# LPC15xx register map
File version: 0.7
CPU: CM3 r2p1, little endian, no MPU, no FPU, 3 interrupt priority bits
Registers are 32-bit, read-write, reset 0x0 unless marked. A register's access mark holds for its fields unless they carry their own. Offsets are from the block's base; [hi:lo] are bit positions.

## CRC — Cyclic Redundancy Check (CRC) engine
Base 0x1C010000
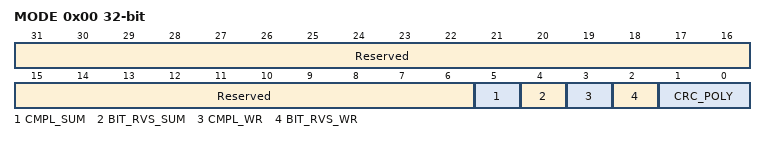
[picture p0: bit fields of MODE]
0x00 MODE — CRC mode register
  [31:6] Reserved — Always 0 when read
  [5] CMPL_SUM — CRC sum complement: 1= 1's complement for CRC_SUM 0=No 1's complement for CRC_SUM
  [4] BIT_RVS_SUM — CRC sum bit order: 1= Bit order reverse for CRC_SUM 0= No bit order reverse for CRC_SUM
  [3] CMPL_WR — Data complement: 1= 1's complement for CRC_WR_DATA 0= No 1's complement for CRC_WR_DATA
  [2] BIT_RVS_WR — Data bit order: 1= Bit order reverse for CRC_WR_DATA (per byte) 0= No bit order reverse for CRC_WR_DATA (per byte)
  [1:0] CRC_POLY — CRC polynom: 1X= CRC-32 polynomial 01= CRC-16 polynomial 00= CRC-CCITT polynomial
0x04 SEED reset 0xFFFF — CRC seed register
  [31:0] CRC_SEED — A write access to this register will load CRC seed value to CRC_SUM register with selected bit order and 1's complement pre-processes. A write access to this register will overrule the CRC calculation in progresses.
0x08 SUM ro reset 0xFFFF — CRC checksum register
  [31:0] CRC_SUM — The most recent CRC sum can be read through this register with selected bit order and 1's complement post-processes.
0x08 WR_DATA wo reset not defined (alternate view of SUM) — CRC data register
  [31:0] CRC_WR_DATA — Data written to this register will be taken to perform CRC calculation with selected bit order and 1's complement pre-process. Any write size 8, 16 or 32-bit are allowed and accept back-to-back transactions.

## WWDT — Windowed Watchdog Timer (WWDT)
Base 0x4002C000
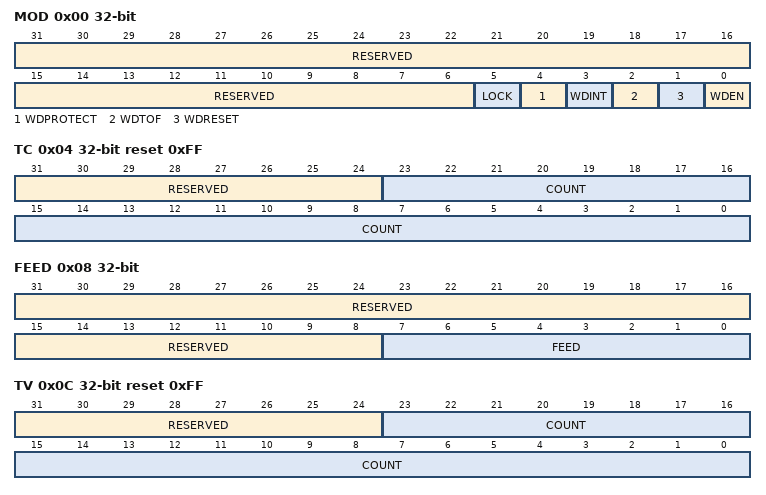
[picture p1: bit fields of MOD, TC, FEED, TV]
0x00 MOD — Watchdog mode register. This register contains the basic mode and status of the Watchdog Timer.
  [31:6] RESERVED — Reserved, user software should not write ones to reserved bits. The value read from a reserved bit is not defined.
  [5] LOCK — A 1 in this bit prevents disabling or powering down the watchdog oscillator. This bit can be set once by software and is only cleared by any reset.
  [4] WDPROTECT — Watchdog update mode. This bit can be set once by software and is only cleared by a reset.
    0=FLEXIBLE (Flexible. The watchdog time-out value (TC) can be changed at any time.); 1=THRESHOLD (Threshold. The watchdog time-out value (TC) can be changed only after the counter is below the value of WDWARNINT and WDWINDOW.)
  [3] WDINT — Warning interrupt flag. Set when the timer reaches the value in WDWARNINT. Cleared by software.
  [2] WDTOF — Watchdog time-out flag. Set when the watchdog timer times out, by a feed error, or by events associated with WDPROTECT. Cleared by software. Causes a chip reset if WDRESET = 1.
  [1] WDRESET — Watchdog reset enable bit. Once this bit has been written with a 1 it cannot be re-written with a 0.
    0=INTERRUPT (Interrupt. A watchdog time-out will not cause a chip reset.); 1=RESET (Reset. A watchdog time-out will cause a chip reset.)
  [0] WDEN — Watchdog enable bit. Once this bit has been written with a 1, it cannot be re-written with a 0. Once this bit is set to one and performing a watchdog feed, the watchdog timer starts running permanently.
    0=STOP (Stop. The watchdog timer is stopped.); 1=RUN (Run. The watchdog timer is running.)
0x04 TC reset 0xFF — Watchdog timer constant register. This 24-bit register determines the time-out value.
  [31:24] RESERVED — Reserved, user software should not write ones to reserved bits. The value read from a reserved bit is not defined.
  [23:0] COUNT — Watchdog time-out value.
0x08 FEED wo reset not defined — Watchdog feed sequence register. Writing 0xAA followed by 0x55 to this register reloads the Watchdog timer with the value contained in WDTC.
  [31:8] RESERVED — Reserved, user software should not write ones to reserved bits. The value read from a reserved bit is not defined.
  [7:0] FEED — Feed value should be 0xAA followed by 0x55.
0x0C TV ro reset 0xFF — Watchdog timer value register. This 24-bit register reads out the current value of the Watchdog timer.
  [31:24] RESERVED — Reserved, user software should not write ones to reserved bits. The value read from a reserved bit is not defined.
  [23:0] COUNT — Counter timer value.
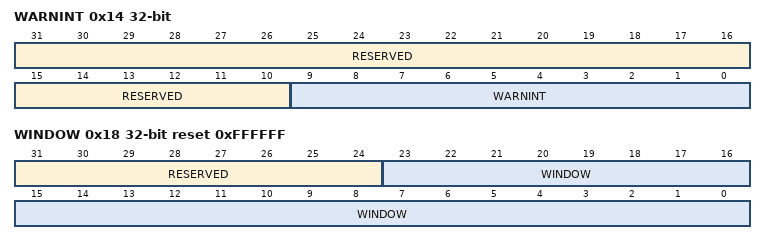
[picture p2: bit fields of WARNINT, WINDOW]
0x14 WARNINT — Watchdog Warning Interrupt compare value.
  [31:10] RESERVED — Reserved, user software should not write ones to reserved bits. The value read from a reserved bit is not defined.
  [9:0] WARNINT — Watchdog warning interrupt compare value.
0x18 WINDOW reset 0xFFFFFF — Watchdog Window compare value.
  [31:24] RESERVED — Reserved, user software should not write ones to reserved bits. The value read from a reserved bit is not defined.
  [23:0] WINDOW — Watchdog window value.
